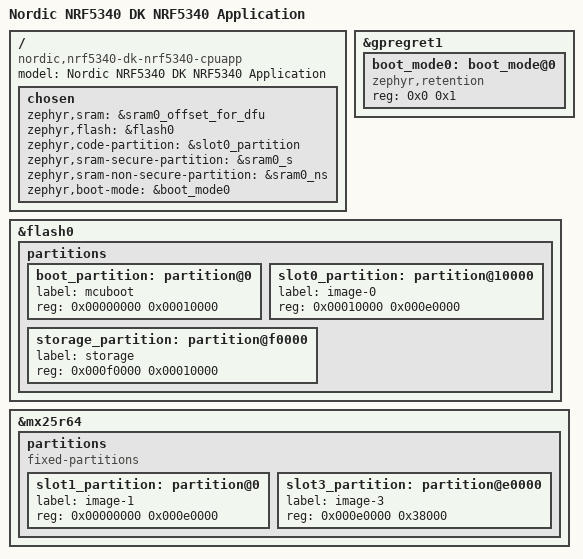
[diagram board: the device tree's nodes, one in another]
/*
 * Copyright (c) 2020-2025 Nordic Semiconductor ASA
 *
 * SPDX-License-Identifier: Apache-2.0
 */

/dts-v1/;
#include <nordic/nrf5340_cpuapp_qkaa.dtsi>
#include "nrf5340_cpuapp_common.dtsi"

/ {
	model = "Nordic NRF5340 DK NRF5340 Application";
	compatible = "nordic,nrf5340-dk-nrf5340-cpuapp";

	chosen {
		zephyr,sram = &sram0_offset_for_dfu;
		zephyr,flash = &flash0;
		zephyr,code-partition = &slot0_partition;
		zephyr,sram-secure-partition = &sram0_s;
		zephyr,sram-non-secure-partition = &sram0_ns;
		zephyr,boot-mode = &boot_mode0;
	};
};

&gpregret1 {
	status = "okay";

	boot_mode0: boot_mode@0 {
		compatible = "zephyr,retention";
		status = "okay";
		reg = <0x0 0x1>;
	};
};

/* Include default memory partition configuration file */
#include <nordic/nrf5340_cpuapp_partition.dtsi>

/delete-node/ &boot_partition;
/delete-node/ &slot0_partition;
/delete-node/ &slot1_partition;
/delete-node/ &storage_partition;

&flash0 {
	partitions {
		boot_partition: partition@0 {
			label = "mcuboot";
			reg = <0x00000000 0x00010000>;
		};

		slot0_partition: partition@10000 {
			label = "image-0";
			reg = <0x00010000 0x000e0000>;
		};

		storage_partition: partition@f0000 {
			label = "storage";
			reg = <0x000f0000 0x00010000>;
		};
	};
};

&mx25r64 {
	partitions {
		compatible = "fixed-partitions";
//		ranges;
		#address-cells = <1>;
		#size-cells = <1>;

		slot1_partition: partition@0 {
			label = "image-1";
			reg = <0x00000000 0x000e0000>;
		};

		slot3_partition: partition@e0000 {
			label = "image-3";
			reg = <0x000e0000 0x38000>;
		};
	};
};
